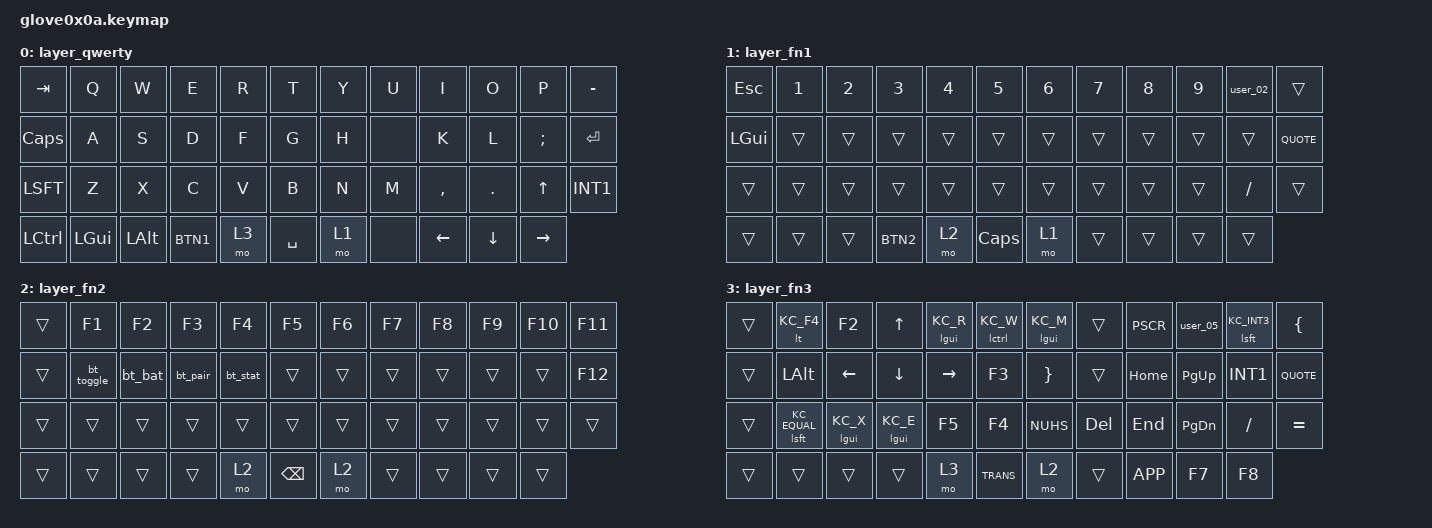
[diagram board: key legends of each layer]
/ {
  keymap {
    compatible = "zmk,keymap";

    layer_qwerty {
      bindings = <
        &kp TAB    &kp Q    &kp W    &kp E    &kp R    &kp T    &kp Y    &kp U    &kp I    &kp O    &kp P    &kp MINUS
        &kp CAPS   &kp A    &kp S    &kp D    &kp F    &kp G    &kp H    &none    &kp K    &kp L    &kp SEMI &kp ENTER
        &kp LSFT   &kp Z    &kp X    &kp C    &kp V    &kp B    &kp N    &kp M    &kp COMMA &kp DOT  &kp UP   &kp INT1
        &kp LCTRL  &kp LGUI &kp LALT &kp BTN1 &mo 3    &kp SPACE &mo 1   &none    &kp LEFT  &kp DOWN &kp RIGHT
      >;
    };

    layer_fn1 {
      bindings = <
        &kp ESC    &kp 1    &kp 2    &kp 3    &kp 4    &kp 5    &kp 6    &kp 7    &kp 8    &kp 9    &user_02        &trans
        &kp LGUI   &trans   &trans   &trans   &trans   &trans   &trans   &trans   &trans   &trans   &trans      &kp QUOTE
        &trans     &trans   &trans   &trans   &trans   &trans   &trans   &trans   &trans   &trans   &kp SLASH   &trans
        &trans     &trans   &trans   &kp BTN2 &mo 2    &kp CAPS &mo 1   &trans   &trans   &trans   &trans
      >;
    };

    layer_fn2 {
      bindings = <
        &trans     &kp F1   &kp F2   &kp F3   &kp F4   &kp F5   &kp F6   &kp F7   &kp F8   &kp F9   &kp F10     &kp F11
        &trans     &bt_toggle &bt_bat &bt_pair &bt_stat &trans &trans   &trans   &trans   &trans   &trans      &kp F12
        &trans     &trans   &trans   &trans   &trans   &trans   &trans   &trans   &trans   &trans   &trans      &trans
        &trans     &trans   &trans   &trans   &mo 2    &kp BSPC &mo 2   &trans   &trans   &trans   &trans
      >;
    };

    layer_fn3 {
      bindings = <
        &trans     &lt KC_F4 &kp F2   &kp UP   &lgui KC_R &lctrl KC_W &lgui KC_M &trans   &kp PSCR  &user_05 &lsft KC_INT3 &kp LBRC
        &trans     &kp LALT &kp LEFT &kp DOWN &kp RIGHT &kp F3      &kp RBRC   &trans   &kp HOME  &kp PG_UP   &kp INT1      &kp QUOTE
        &trans     &lsft KC_EQUAL &lgui KC_X &lgui KC_E &kp F5      &kp F4     &kp NUHS  &kp DEL   &kp END    &kp PG_DN     &kp SLASH    &kp EQL
        &trans     &trans   &trans   &trans   &mo 3     &kp TRANS   &mo 2      &trans   &kp APP   &kp F7      &kp F8
      >;
    };
  };
};
